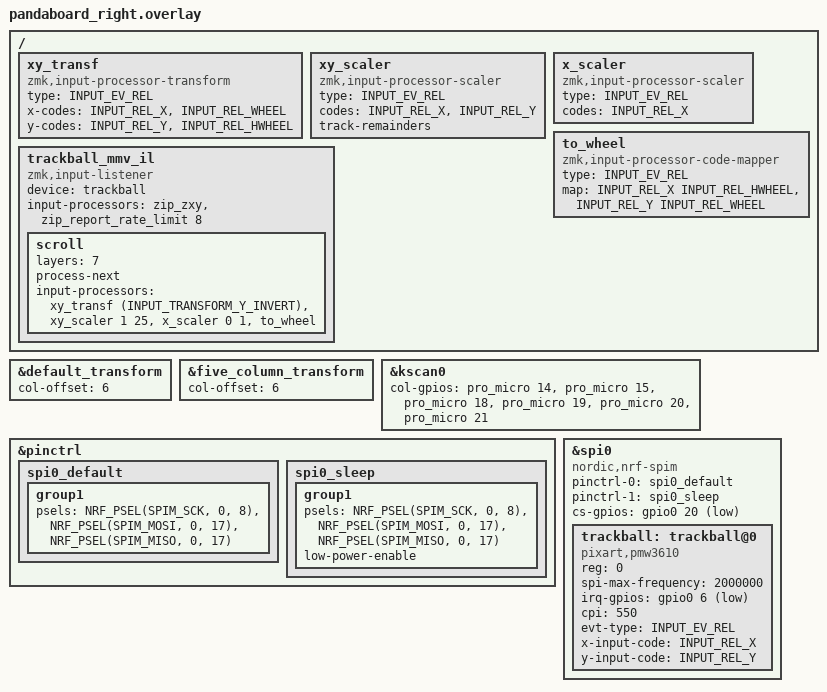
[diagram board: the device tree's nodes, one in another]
#define INPUT_EV_KEY 0x01               /**< Key event */
#define INPUT_EV_REL 0x02               /**< Relative coordinate event */
#define INPUT_EV_ABS 0x03               /**< Absolute coordinate event */
#define INPUT_EV_MSC 0x04               /**< Miscellaneous event */
#define INPUT_EV_VENDOR_START 0xf0      /**< Vendor specific event start */
#define INPUT_EV_VENDOR_STOP 0xff       /**< Vendor specific event stop */

#define INPUT_REL_X 0x00                /**< Relative X coordinate */
#define INPUT_REL_Y 0x01                /**< Relative Y coordinate */
#define INPUT_REL_WHEEL 0x08            /**< Relative wheel coordinate */
#define INPUT_REL_HWHEEL 0x06           /**< Relative horizontal wheel coordinate */
#define INPUT_REL_MISC 0x09             /**< Relative misc coordinate */

#include "pandaboard.dtsi"
#include <zephyr/dt-bindings/input/input-event-codes.h>
#include <dt-bindings/zmk/input_transform.h>
#include <input/processors/report_rate_limit.dtsi>
#include <input/processors/xyz.dtsi>

&default_transform {
    col-offset = <6>;
};

&five_column_transform {
    col-offset = <6>;
};

&kscan0 {
    col-gpios
        = <&pro_micro 14 GPIO_ACTIVE_HIGH>
        , <&pro_micro 15 GPIO_ACTIVE_HIGH>
        , <&pro_micro 18 GPIO_ACTIVE_HIGH>
        , <&pro_micro 19 GPIO_ACTIVE_HIGH>
        , <&pro_micro 20 GPIO_ACTIVE_HIGH>
        , <&pro_micro 21 GPIO_ACTIVE_HIGH>
        ;
};

&pinctrl {
    spi0_default: spi0_default {
        group1 {
            psels = <NRF_PSEL(SPIM_SCK, 0, 8)>,
                <NRF_PSEL(SPIM_MOSI, 0, 17)>,
                <NRF_PSEL(SPIM_MISO, 0, 17)>;
        };
    };

    spi0_sleep: spi0_sleep {
        group1 {
            psels = <NRF_PSEL(SPIM_SCK, 0, 8)>,
                <NRF_PSEL(SPIM_MOSI, 0, 17)>,
                <NRF_PSEL(SPIM_MISO, 0, 17)>;
            low-power-enable;
        };
    };
};

&spi0 {
    status = "okay";
    compatible = "nordic,nrf-spim";
    pinctrl-0 = <&spi0_default>;
    pinctrl-1 = <&spi0_sleep>;
    pinctrl-names = "default", "sleep";
    cs-gpios = <&gpio0 20 GPIO_ACTIVE_LOW>;

    trackball: trackball@0 {
        status = "okay";
        compatible = "pixart,pmw3610";
        reg = <0>;
        spi-max-frequency = <2000000>;
        irq-gpios = <&gpio0 6 (GPIO_ACTIVE_LOW | GPIO_PULL_UP)>;
        cpi = <550>;
        evt-type = <INPUT_EV_REL>;
        x-input-code = <INPUT_REL_X>;
        y-input-code = <INPUT_REL_Y>;
        /*
        *force-awake;
        *force-awake-4ms-mode;
        */
    };
};

/ {
    xy_transf: xy_transf {
            compatible = "zmk,input-processor-transform";
            #input-processor-cells = <1>;
            type = <INPUT_EV_REL>;
            x-codes = <INPUT_REL_X>, <INPUT_REL_WHEEL>;
            y-codes = <INPUT_REL_Y>, <INPUT_REL_HWHEEL>;
    };
    xy_scaler: xy_scaler {
            compatible = "zmk,input-processor-scaler";
            #input-processor-cells = <2>;
            type = <INPUT_EV_REL>;
            codes = <INPUT_REL_X>, <INPUT_REL_Y>;
            track-remainders;
    };
    x_scaler: x_scaler {
            compatible = "zmk,input-processor-scaler";
            #input-processor-cells = <2>;
            type = <INPUT_EV_REL>;
            codes = <INPUT_REL_X>;
    };
    to_wheel: to_wheel {
            compatible = "zmk,input-processor-code-mapper";
            #input-processor-cells = <0>;
            type = <INPUT_EV_REL>;
            map = <INPUT_REL_X INPUT_REL_HWHEEL>
                , <INPUT_REL_Y INPUT_REL_WHEEL>;
    };

    trackball_mmv_il {
        compatible = "zmk,input-listener";
        device = <&trackball>;
        input-processors = <&zip_zxy>, <&zip_report_rate_limit 8>;
        scroll {
                layers = <7>;
                process-next;
                input-processors = <&xy_transf (INPUT_TRANSFORM_Y_INVERT)>
                                , <&xy_scaler 1 25>, <&x_scaler 0 1>
                                , <&to_wheel>;
        };
    };
};
